VERSION ""

NS_ :

BS_:

BU_: FOO BAR

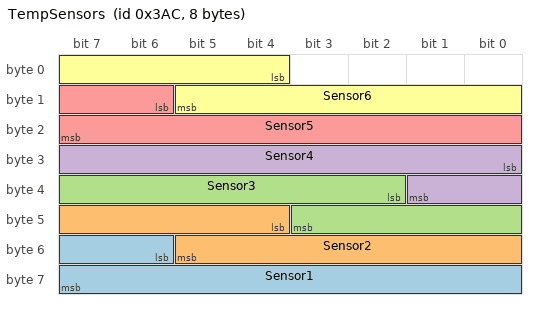
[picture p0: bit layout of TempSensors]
BO_ 940 TempSensors: 8 FOO
	SG_ Sensor1 : 54|10@1- (0.2,0) [0|0] "degC" BAR
	SG_ Sensor2 : 44|10@1- (0.2,0) [0|0] "degC" BAR
	SG_ Sensor3 : 34|10@1- (0.2,0) [0|0] "degC" BAR
	SG_ Sensor4 : 24|10@1- (0.2,0) [0|0] "degC" BAR
	SG_ Sensor5 : 14|10@1- (0.2,0) [0|0] "degC" BAR
	SG_ Sensor6 : 4|10@1- (0.2,0) [0|0] "degC" BAR

BO_ 581 VehicleInfo: 8 BAR
	SG_ WheelSpeed : 26|32@0+ (0.00390625,0) [0|250.996] "km/h" FOO
	SG_ RequestedSpeed : 3|24@0+ (0.00390625,0) [0|250.996] "km/h" FOO

CM_ BO_ 940 "Temperature Sensor Values";
CM_ BO_ 581 "Pack Contactor States";
CM_ SG_ 581 WheelSpeed "Wheel-Based Vehicle Speed: Speed of the vehicle as calculated from wheel or tailshaft speed.";
BA_DEF_ SG_  "SPN" INT 0 524287;
BA_DEF_ BO_  "VFrameFormat" ENUM  "StandardCAN","ExtendedCAN","reserved","J1939PG";
BA_DEF_  "DatabaseVersion" STRING ;
BA_DEF_  "BusType" STRING ;
BA_DEF_  "ProtocolType" STRING ;
BA_DEF_  "DatabaseCompiler" STRING ;
BA_DEF_DEF_  "SPN" 0;
BA_DEF_DEF_  "VFrameFormat" "J1939PG";
BA_DEF_DEF_  "DatabaseVersion" "DEMO PLUS";
BA_DEF_DEF_  "BusType" "";
BA_DEF_DEF_  "ProtocolType" "";
BA_DEF_DEF_  "DatabaseCompiler" "";
BA_ "ProtocolType" "J1939";
BA_ "BusType" "CAN";
BA_ "DatabaseCompiler" "CSS ELECTRONICS (WWW.CSSELECTRONICS.COM)";
BA_ "DatabaseVersion" "1.0.0";
BA_ "SPN" SG_ 2364540158 EngineSpeed 190;
BA_ "SPN" SG_ 2566844926 WheelBasedVehicleSpeed 84;
